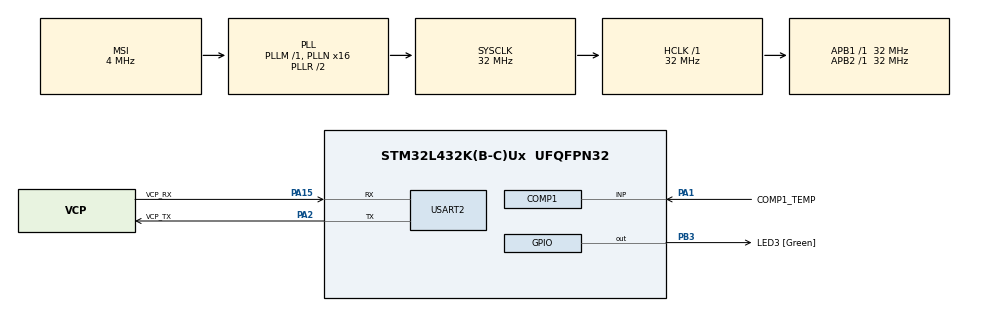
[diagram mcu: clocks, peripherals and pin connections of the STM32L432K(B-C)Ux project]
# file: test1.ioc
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COMP1.Hysteresis=COMP_HYSTERESIS_LOW
COMP1.Mode=COMP_POWERMODE_MEDIUMSPEED
COMP1.TriggerMode=COMP_TRIGGERMODE_IT_RISING
FREERTOS.Tasks01=defaultTask,0,128,StartDefaultTask,Default,NULL,Dynamic,NULL,NULL;myTask,-3,128,StartTask02,Default,NULL,Dynamic,NULL,NULL
Mcu.Family=STM32L4
Mcu.Name=STM32L432K(B-C)Ux
Mcu.Package=UFQFPN32
NVIC.COMP_IRQn=true\:5\:0\:false\:false\:true\:true\:false\:true
NVIC.PriorityGroup=NVIC_PRIORITYGROUP_4
PA0.GPIO_Label=MCO [High speed clock in]
PA0.Mode=HSE-External-Clock-Source-for-LittleOrca
PA0.Signal=RCC_CK_IN
PA1.GPIO_Label=COMP1_TEMP
PA1.Mode=INP
PA1.Signal=COMP1_INP
PA13\ (JTMS-SWDIO).GPIO_Label=SWDIO
PA13\ (JTMS-SWDIO).Mode=Serial_Wire
PA13\ (JTMS-SWDIO).Signal=SYS_JTMS-SWDIO
PA14\ (JTCK-SWCLK).GPIO_Label=SWCLK
PA14\ (JTCK-SWCLK).Mode=Serial_Wire
PA14\ (JTCK-SWCLK).Signal=SYS_JTCK-SWCLK
PA15\ (JTDI).GPIO_Label=VCP_RX
PA15\ (JTDI).Mode=Asynchronous
PA15\ (JTDI).Signal=USART2_RX
PA2.GPIO_Label=VCP_TX
PA2.Mode=Asynchronous
PA2.Signal=USART2_TX
PB3\ (JTDO-TRACESWO).GPIO_Label=LED3 [Green]
PB3\ (JTDO-TRACESWO).Signal=GPIO_Output
PC14-OSC32_IN\ (PC14).Mode=LSE-External-Oscillator
PC14-OSC32_IN\ (PC14).Signal=RCC_OSC32_IN
PC15-OSC32_OUT\ (PC15).Mode=LSE-External-Oscillator
PC15-OSC32_OUT\ (PC15).Signal=RCC_OSC32_OUT
ProjectManager.HeapSize=0x200
ProjectManager.StackSize=0x400
ProjectManager.TargetToolchain=Makefile
RCC.AHBFreq_Value=32000000
RCC.APB1Freq_Value=32000000
RCC.APB1TimFreq_Value=32000000
RCC.APB2Freq_Value=32000000
RCC.APB2TimFreq_Value=32000000
RCC.CortexFreq_Value=32000000
RCC.HCLKFreq_Value=32000000
RCC.HSE_VALUE=8000000
RCC.HSI16_VALUE=16000000
RCC.HSI48_VALUE=48000000
RCC.HSI_VALUE=16000000
RCC.MSI_VALUE=4000000
RCC.PLLMUL=RCC_PLLMUL_4
RCC.PLLN=16
RCC.SYSCLKFreq_VALUE=32000000
RCC.SYSCLKSource=RCC_SYSCLKSOURCE_PLLCLK
RCC.VCOOutputFreq_Value=64000000
USART2.VirtualMode-Asynchronous=VM_ASYNC
VP_COMP1_VS_VREFINT12.Mode=VREFINT_12
VP_FREERTOS_VS_CMSIS_V1.Mode=CMSIS_V1
board=NUCLEO-L432KC

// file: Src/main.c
/* USER CODE BEGIN Header */
/**
  ******************************************************************************
  * @file           : main.c
  * @brief          : Main program body
  ******************************************************************************
  * @attention
  *
  * <h2><center>&copy; Copyright (c) 2019 STMicroelectronics.
  * All rights reserved.</center></h2>
  *
  * This software component is licensed by ST under Ultimate Liberty license
  * SLA0044, the "License"; You may not use this file except in compliance with
  * the License. You may obtain a copy of the License at:
  *                             www.st.com/SLA0044
  *
  ******************************************************************************
  */
/* USER CODE END Header */

#include "main.h"
#include "cmsis_os.h"
#include "comp.h"
#include "usart.h"
#include "gpio.h"

/* USER CODE BEGIN PV */

volatile int cntX;

/* USER CODE END PV */

void SystemClock_Config(void);
void MX_FREERTOS_Init(void);

int main(void) {

    /* MCU Configuration--------------------------------------------------------*/

    /* Reset of all peripherals, Initializes the Flash interface and the Systick. */
    HAL_Init();

    /* Configure the system clock */
    SystemClock_Config();

    /* Initialize all configured peripherals */
    MX_GPIO_Init();
    MX_COMP1_Init();
    MX_USART2_UART_Init();

    /* Call init function for freertos objects (in freertos.c) */
    MX_FREERTOS_Init();

    /* Start scheduler */
    osKernelStart();

    /* We should never get here as control is now taken by the scheduler */

    /* Infinite loop */
    while (1) {

    }
}

void SystemClock_Config(void) {
    RCC_OscInitTypeDef RCC_OscInitStruct = {0};
    RCC_ClkInitTypeDef RCC_ClkInitStruct = {0};
    RCC_PeriphCLKInitTypeDef PeriphClkInit = {0};

    /** Configure LSE Drive Capability
    */
    HAL_PWR_EnableBkUpAccess();
    __HAL_RCC_LSEDRIVE_CONFIG(RCC_LSEDRIVE_LOW);
    /** Initializes the CPU, AHB and APB busses clocks
    */
    RCC_OscInitStruct.OscillatorType = RCC_OSCILLATORTYPE_LSE|RCC_OSCILLATORTYPE_MSI;
    RCC_OscInitStruct.LSEState = RCC_LSE_ON;
    RCC_OscInitStruct.MSIState = RCC_MSI_ON;
    RCC_OscInitStruct.MSICalibrationValue = 0;
    RCC_OscInitStruct.MSIClockRange = RCC_MSIRANGE_6;
    RCC_OscInitStruct.PLL.PLLState = RCC_PLL_ON;
    RCC_OscInitStruct.PLL.PLLSource = RCC_PLLSOURCE_MSI;
    RCC_OscInitStruct.PLL.PLLM = 1;
    RCC_OscInitStruct.PLL.PLLN = 16;
    RCC_OscInitStruct.PLL.PLLP = RCC_PLLP_DIV7;
    RCC_OscInitStruct.PLL.PLLQ = RCC_PLLQ_DIV2;
    RCC_OscInitStruct.PLL.PLLR = RCC_PLLR_DIV2;
    if (HAL_RCC_OscConfig(&RCC_OscInitStruct) != HAL_OK) {
        Error_Handler();
    }
    /** Initializes the CPU, AHB and APB busses clocks
    */
    RCC_ClkInitStruct.ClockType = RCC_CLOCKTYPE_HCLK|RCC_CLOCKTYPE_SYSCLK
                                  |RCC_CLOCKTYPE_PCLK1|RCC_CLOCKTYPE_PCLK2;
    RCC_ClkInitStruct.SYSCLKSource = RCC_SYSCLKSOURCE_PLLCLK;
    RCC_ClkInitStruct.AHBCLKDivider = RCC_SYSCLK_DIV1;
    RCC_ClkInitStruct.APB1CLKDivider = RCC_HCLK_DIV1;
    RCC_ClkInitStruct.APB2CLKDivider = RCC_HCLK_DIV1;

    if (HAL_RCC_ClockConfig(&RCC_ClkInitStruct, FLASH_LATENCY_1) != HAL_OK) {
        Error_Handler();
    }
    PeriphClkInit.PeriphClockSelection = RCC_PERIPHCLK_USART2;
    PeriphClkInit.Usart2ClockSelection = RCC_USART2CLKSOURCE_PCLK1;
    if (HAL_RCCEx_PeriphCLKConfig(&PeriphClkInit) != HAL_OK) {
        Error_Handler();
    }
    /** Configure the main internal regulator output voltage
    */
    if (HAL_PWREx_ControlVoltageScaling(PWR_REGULATOR_VOLTAGE_SCALE1) != HAL_OK) {
        Error_Handler();
    }
    /** Enable MSI Auto calibration
    */
    HAL_RCCEx_EnableMSIPLLMode();
}

void Error_Handler(void) {
}

/************************ (C) COPYRIGHT STMicroelectronics *****END OF FILE****/

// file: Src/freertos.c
/* USER CODE BEGIN Header */
/**
  ******************************************************************************
  * File Name          : freertos.c
  * Description        : Code for freertos applications
  ******************************************************************************
  * @attention
  *
  * <h2><center>&copy; Copyright (c) 2019 STMicroelectronics.
  * All rights reserved.</center></h2>
  *
  * This software component is licensed by ST under Ultimate Liberty license
  * SLA0044, the "License"; You may not use this file except in compliance with
  * the License. You may obtain a copy of the License at:
  *                             www.st.com/SLA0044
  *
  ******************************************************************************
  */
/* USER CODE END Header */

#include "FreeRTOS.h"
#include "task.h"
#include "main.h"
#include "cmsis_os.h"

/* USER CODE BEGIN Includes */
#include <string.h>
#include <stdio.h>
#include <usart.h>
#include <comp.h>
/* USER CODE END Includes */

osThreadId defaultTaskHandle;
osThreadId myTaskHandle;

void StartDefaultTask(void const * argument);
void StartTask02(void const * argument);

void MX_FREERTOS_Init(void); /* (MISRA C 2004 rule 8.1) */

void MX_FREERTOS_Init(void) {

    /* Create the thread(s) */
    /* definition and creation of defaultTask */
    osThreadDef(defaultTask, StartDefaultTask, osPriorityNormal, 0, 128);
    defaultTaskHandle = osThreadCreate(osThread(defaultTask), NULL);

    /* definition and creation of myTask */
    osThreadDef(myTask, StartTask02, osPriorityIdle, 0, 128);
    myTaskHandle = osThreadCreate(osThread(myTask), NULL);

}

void StartDefaultTask(void const * argument) {

    for(;;) {
        osDelay(1);
    }
}

void StartTask02(void const * argument) {
    /* USER CODE BEGIN StartTask02 */
    /* Infinite loop */
    char buffer[10];
    int cnt = 0;
    /* HAL_GPIO_WritePin(GPIOB, GPIO_PIN_3, GPIO_PIN_SET); */
    /* HAL_GPIO_WritePin(GPIOB, GPIO_PIN_3, GPIO_PIN_RESET); */
    HAL_COMP_Start(&hcomp1);
    for(;;) {
        cnt += 1;
        snprintf(buffer, sizeof(buffer), "%4i\n", cntX);
        HAL_UART_Transmit(&huart2, (uint8_t*)&buffer[0], strlen(buffer), 10);
        HAL_GPIO_TogglePin(GPIOB, GPIO_PIN_3);
        HAL_Delay(100);
        osDelay(1);
    }
    /* USER CODE END StartTask02 */
}

/************************ (C) COPYRIGHT STMicroelectronics *****END OF FILE****/
